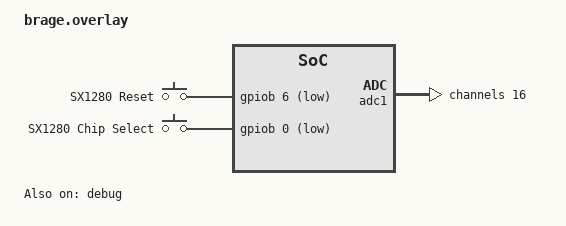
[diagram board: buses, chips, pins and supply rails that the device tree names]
// Board-specific overlay for Brage STM32U575 board
// Use this overlay for testing specific configurations

&adc1 {
	// Temperature sensor configuration
	#address-cells = <1>;
	#size-cells = <0>;
	
	// Thermistor channel (PB1 - ADC1_IN16)
	thermistor: channel@10 {
		reg = <16>;
		zephyr,gain = "ADC_GAIN_1";
		zephyr,reference = "ADC_REF_INTERNAL";
		zephyr,acquisition-time = <ADC_ACQ_TIME(ADC_ACQ_TIME_MICROSECONDS, 2)>;
		zephyr,resolution = <12>;
		zephyr,oversampling = <8>;
	};
};

// GPIO aliases for easier access
/ {
	aliases {
		// LoRa control pins
		lora-reset = &sx_reset;
		lora-busy = &sx_busy;
		lora-cs = &sx_cs;
		
		// Power amplifier control
		pa-enable = &pa_enable;
		pa-tx-enable = &pa_tx_enable;
		
		// Status LEDs
		status-tx = &led_tx;
		status-rx = &led_rx;
		status-green = &led_green;
		status-blue = &led_blue;
		
		// Sensors
		thermistor = &thermistor;
	};
	
	// Additional GPIO definitions
	gpio_pins {
		compatible = "gpio-keys";
		
		sx_reset: sx_reset {
			gpios = <&gpiob 6 GPIO_ACTIVE_LOW>;
			label = "SX1280 Reset";
		};

		sx_cs: sx_cs {
			gpios = <&gpiob 0 GPIO_ACTIVE_LOW>;
			label = "SX1280 Chip Select";
		};
	};
};

// Enable debug interfaces
&debug {
	status = "okay";
};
